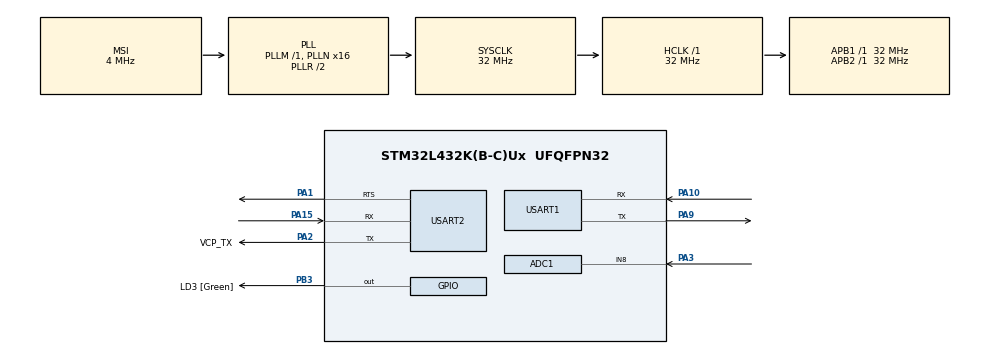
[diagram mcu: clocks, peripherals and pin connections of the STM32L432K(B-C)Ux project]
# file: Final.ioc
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ADC1.Channel-0\#ChannelRegularConversion=ADC_CHANNEL_8
ADC1.ContinuousConvMode=ENABLE
ADC1.NbrOfConversionFlag=1
ADC1.OffsetNumber-0\#ChannelRegularConversion=ADC_OFFSET_NONE
ADC1.Rank-0\#ChannelRegularConversion=1
ADC1.SamplingTime-0\#ChannelRegularConversion=ADC_SAMPLETIME_2CYCLES_5
ADC1.master=1
Mcu.Family=STM32L4
Mcu.Name=STM32L432K(B-C)Ux
Mcu.Package=UFQFPN32
NVIC.PriorityGroup=NVIC_PRIORITYGROUP_4
PA0.GPIO_Label=MCO [High speed clock in]
PA0.Mode=HSE-External-Clock-Source-for-LittleOrca
PA0.Signal=RCC_CK_IN
PA1.Mode=RTS_Only
PA1.Signal=USART2_RTS
PA10.Mode=Asynchronous
PA10.Signal=USART1_RX
PA13\ (JTMS-SWDIO).GPIO_Label=SWDIO
PA13\ (JTMS-SWDIO).Mode=Serial_Wire
PA13\ (JTMS-SWDIO).Signal=SYS_JTMS-SWDIO
PA14\ (JTCK-SWCLK).GPIO_Label=SWCLK
PA14\ (JTCK-SWCLK).Mode=Serial_Wire
PA14\ (JTCK-SWCLK).Signal=SYS_JTCK-SWCLK
PA15\ (JTDI).Mode=Asynchronous
PA15\ (JTDI).Signal=USART2_RX
PA2.GPIO_Label=VCP_TX
PA2.Mode=Asynchronous
PA2.Signal=USART2_TX
PA3.Signal=ADCx_IN8
PA9.Mode=Asynchronous
PA9.Signal=USART1_TX
PB3\ (JTDO-TRACESWO).GPIO_Label=LD3 [Green]
PB3\ (JTDO-TRACESWO).Signal=GPIO_Output
PC14-OSC32_IN\ (PC14).Mode=LSE-External-Oscillator
PC14-OSC32_IN\ (PC14).Signal=RCC_OSC32_IN
PC15-OSC32_OUT\ (PC15).Mode=LSE-External-Oscillator
PC15-OSC32_OUT\ (PC15).Signal=RCC_OSC32_OUT
ProjectManager.HeapSize=0x200
ProjectManager.StackSize=0x400
ProjectManager.TargetToolchain=TrueSTUDIO
RCC.AHBFreq_Value=32000000
RCC.APB1Freq_Value=32000000
RCC.APB1TimFreq_Value=32000000
RCC.APB2Freq_Value=32000000
RCC.APB2TimFreq_Value=32000000
RCC.CortexFreq_Value=32000000
RCC.HCLKFreq_Value=32000000
RCC.HSE_VALUE=8000000
RCC.HSI16_VALUE=16000000
RCC.HSI48_VALUE=48000000
RCC.HSI_VALUE=16000000
RCC.MSI_VALUE=4000000
RCC.PLLMUL=RCC_PLLMUL_4
RCC.PLLN=16
RCC.SYSCLKFreq_VALUE=32000000
RCC.SYSCLKSource=RCC_SYSCLKSOURCE_PLLCLK
RCC.VCOOutputFreq_Value=64000000
SH.ADCx_IN8.0=ADC1_IN8,IN8-Single-Ended
USART1.VirtualMode-Asynchronous=VM_ASYNC
USART2.VirtualMode-Asynchronous=VM_ASYNC
board=NUCLEO-L432KC

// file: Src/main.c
/* USER CODE BEGIN Header */
/**
 ******************************************************************************
 * @file           : main.c
 * @brief          : Main program body
 ******************************************************************************
 ** This notice applies to any and all portions of this file
 * that are not between comment pairs USER CODE BEGIN and
 * USER CODE END. Other portions of this file, whether
 * inserted by the user or by software development tools
 * are owned by their respective copyright owners.
 *
 * COPYRIGHT(c) 2019 STMicroelectronics
 *
 * Redistribution and use in source and binary forms, with or without modification,
 * are permitted provided that the following conditions are met:
 *   1. Redistributions of source code must retain the above copyright notice,
 *      this list of conditions and the following disclaimer.
 *   2. Redistributions in binary form must reproduce the above copyright notice,
 *      this list of conditions and the following disclaimer in the documentation
 *      and/or other materials provided with the distribution.
 *   3. Neither the name of STMicroelectronics nor the names of its contributors
 *      may be used to endorse or promote products derived from this software
 *      without specific prior written permission.
 *
 * THIS SOFTWARE IS PROVIDED BY THE COPYRIGHT HOLDERS AND CONTRIBUTORS "AS IS"
 * AND ANY EXPRESS OR IMPLIED WARRANTIES, INCLUDING, BUT NOT LIMITED TO, THE
 * IMPLIED WARRANTIES OF MERCHANTABILITY AND FITNESS FOR A PARTICULAR PURPOSE ARE
 * DISCLAIMED. IN NO EVENT SHALL THE COPYRIGHT HOLDER OR CONTRIBUTORS BE LIABLE
 * FOR ANY DIRECT, INDIRECT, INCIDENTAL, SPECIAL, EXEMPLARY, OR CONSEQUENTIAL
 * DAMAGES (INCLUDING, BUT NOT LIMITED TO, PROCUREMENT OF SUBSTITUTE GOODS OR
 * SERVICES; LOSS OF USE, DATA, OR PROFITS; OR BUSINESS INTERRUPTION) HOWEVER
 * CAUSED AND ON ANY THEORY OF LIABILITY, WHETHER IN CONTRACT, STRICT LIABILITY,
 * OR TORT (INCLUDING NEGLIGENCE OR OTHERWISE) ARISING IN ANY WAY OUT OF THE USE
 * OF THIS SOFTWARE, EVEN IF ADVISED OF THE POSSIBILITY OF SUCH DAMAGE.
 *
 ******************************************************************************
 */
/* USER CODE END Header */

#include "main.h"
#include "stm32l4xx_hal.h"
#include "math.h"
#define ADC_READING      4096
#define REF_VOLTAGE      3.3
#define REF_RESISTANCE   1650
#define LUX_SCALAR       12518931
#define LUX_CALC         -1.405

unsigned char start_delimeter = 0x7E;
unsigned char length_MSB = 0x00;
unsigned char length_LSB = 0x0C;
unsigned char frame_type = 0x01;		//Transmit Request Frame, API identifier
unsigned char frame_id = 0x01;//Identifies data frame to enable respond frame, API Frame ID
unsigned char option = 0x00;
unsigned char destination_add_MSB = 0xAB;
unsigned char destination_add_LSB = 0x01;

ADC_HandleTypeDef hadc1;

UART_HandleTypeDef huart1;
UART_HandleTypeDef huart2;

void SystemClock_Config(void);
static void MX_GPIO_Init(void);
static void MX_ADC1_Init(void);
static void MX_USART1_UART_Init(void);
static void MX_USART2_UART_Init(void);
void HAL_ADC_ConvCpltCallback(ADC_HandleTypeDef* hadc);
int get_adc_value(void);
void send_to_pc(int adc_value);
void adc_channel(int channel);
int get_sorted_value();
int calculate_lux(int adc_value);

volatile uint16_t adc_value = 0;
int lux;

void send_to_xbee(char dataHexa[8]) {
	int sum2 = 0x00;
	int sum1 = frame_type + frame_id + destination_add_MSB + destination_add_LSB
			+ option;
	for (int i = 0; i < strlen(dataHexa); i++) {
		sum2 += dataHexa[i];
	}
	int sum = 0;
	sum = sum1 + sum2;
	unsigned char two_last_digit = sum & 0xFF;
	unsigned char checksum = 255 - two_last_digit;
	unsigned char message[16] = { start_delimeter, length_MSB, length_LSB,
			frame_type, frame_id, destination_add_MSB, destination_add_LSB,
			option, 0, 0, 0, 0, 0, 0, 0, checksum };
	for (int i = 0; i < 7; i++) {
		message[8 + i] = dataHexa[i];
	}
	HAL_UART_Transmit(&huart1, message, 16, 100);
	HAL_UART_Transmit(&huart2, message, 16, 100);
}

int main(void) {

	/* MCU Configuration--------------------------------------------------------*/

	/* Reset of all peripherals, Initializes the Flash interface and the Systick. */
	HAL_Init();

	/* Configure the system clock */
	SystemClock_Config();

	/* Initialize all configured peripherals */
	MX_GPIO_Init();
	MX_ADC1_Init();
	MX_USART1_UART_Init();
	MX_USART2_UART_Init();
//HAL_ADC_Start_IT(&hadc1);
//HAL_ADC_ConvCpltCallback(&hadc1);
	/* Infinite loop */
	/* USER CODE BEGIN WHILE */
	while (1) {

		char msg1[8]="";
		adc_channel(8);
		adc_value = get_sorted_value();
		lux = adc_value;
		 //lux=adc_value/100;
		//send_to_pc(lux);
		/* USER CODE BEGIN 3 */
		sprintf(msg1, "%d", lux);
		send_to_xbee(msg1);
		HAL_Delay(3000);
	}
	/* USER CODE END 3 */
}

int calculate_lux(int adc_value) {
	int vol1, ldr_vol, lux, ldr_resistor;
	vol1 = adc_value / ADC_READING * REF_VOLTAGE;
	ldr_vol = REF_VOLTAGE - vol1;
	ldr_resistor = ldr_vol / vol1 * REF_RESISTANCE;
	lux = LUX_SCALAR * pow(ldr_resistor, LUX_CALC);
	return lux;
}
int get_sorted_value() {
	int raw_value[5] = { 0 };
	int i = 0;
	int k = 0;
	int apu = 0;

	for (k = 0; k < 4; k++) {
		raw_value[k] = get_adc_value();
		HAL_Delay(100);
	}

	for (k = 0; k < 4; k++) {
		for (i = 0; i < 4; i++) {
			if (raw_value[i] > raw_value[i + 1]) {
				apu = raw_value[i];
				raw_value[i] = raw_value[i + 1];
				raw_value[i + 1] = apu;
			} else {

			}
		}
	}
	return raw_value[2];
}
void HAL_ADC_ConvCpltCallback(ADC_HandleTypeDef* hadc) {
	if (hadc->Instance == hadc1.Instance) {
		adc_value = HAL_ADC_GetValue(hadc);
	}
}

void send_to_pc(int lux) {
	char msg6[] = { "Lux: " };
	HAL_UART_Transmit(&huart2, (uint8_t*) msg6, 5, 10);
	char msg1[1] = { 0 };
	sprintf(msg1, "%d", lux);
	HAL_UART_Transmit(&huart2, (uint8_t*) msg1, 4, 10);
}
int get_adc_value(void) {
	HAL_ADC_Start(&hadc1);
	HAL_ADC_PollForConversion(&hadc1, 10000);
	adc_value = HAL_ADC_GetValue(&hadc1);
	HAL_ADC_Stop(&hadc1);
	return adc_value;
}

void adc_channel(int channel) {
	ADC_ChannelConfTypeDef sConfig;
	sConfig.Channel = ADC_CHANNEL_8;
	sConfig.Rank = ADC_REGULAR_RANK_1;
	sConfig.SamplingTime = ADC_SAMPLETIME_2CYCLES_5;
	sConfig.SingleDiff = ADC_SINGLE_ENDED;
	sConfig.OffsetNumber = ADC_OFFSET_NONE;
	sConfig.Offset = 0;
	HAL_ADC_ConfigChannel(&hadc1, &sConfig);

}
void SystemClock_Config(void) {
	RCC_OscInitTypeDef RCC_OscInitStruct = { 0 };
	RCC_ClkInitTypeDef RCC_ClkInitStruct = { 0 };
	RCC_PeriphCLKInitTypeDef PeriphClkInit = { 0 };

	/**Configure LSE Drive Capability
	 */
	HAL_PWR_EnableBkUpAccess();
	__HAL_RCC_LSEDRIVE_CONFIG(RCC_LSEDRIVE_LOW);
	/**Initializes the CPU, AHB and APB busses clocks
	 */
	RCC_OscInitStruct.OscillatorType = RCC_OSCILLATORTYPE_LSE
			| RCC_OSCILLATORTYPE_MSI;
	RCC_OscInitStruct.LSEState = RCC_LSE_ON;
	RCC_OscInitStruct.MSIState = RCC_MSI_ON;
	RCC_OscInitStruct.MSICalibrationValue = 0;
	RCC_OscInitStruct.MSIClockRange = RCC_MSIRANGE_6;
	RCC_OscInitStruct.PLL.PLLState = RCC_PLL_ON;
	RCC_OscInitStruct.PLL.PLLSource = RCC_PLLSOURCE_MSI;
	RCC_OscInitStruct.PLL.PLLM = 1;
	RCC_OscInitStruct.PLL.PLLN = 16;
	RCC_OscInitStruct.PLL.PLLP = RCC_PLLP_DIV7;
	RCC_OscInitStruct.PLL.PLLQ = RCC_PLLQ_DIV2;
	RCC_OscInitStruct.PLL.PLLR = RCC_PLLR_DIV2;
	if (HAL_RCC_OscConfig(&RCC_OscInitStruct) != HAL_OK) {
		Error_Handler();
	}
	/**Initializes the CPU, AHB and APB busses clocks
	 */
	RCC_ClkInitStruct.ClockType = RCC_CLOCKTYPE_HCLK | RCC_CLOCKTYPE_SYSCLK
			| RCC_CLOCKTYPE_PCLK1 | RCC_CLOCKTYPE_PCLK2;
	RCC_ClkInitStruct.SYSCLKSource = RCC_SYSCLKSOURCE_PLLCLK;
	RCC_ClkInitStruct.AHBCLKDivider = RCC_SYSCLK_DIV1;
	RCC_ClkInitStruct.APB1CLKDivider = RCC_HCLK_DIV1;
	RCC_ClkInitStruct.APB2CLKDivider = RCC_HCLK_DIV1;

	if (HAL_RCC_ClockConfig(&RCC_ClkInitStruct, FLASH_LATENCY_1) != HAL_OK) {
		Error_Handler();
	}
	PeriphClkInit.PeriphClockSelection = RCC_PERIPHCLK_USART1
			| RCC_PERIPHCLK_USART2 | RCC_PERIPHCLK_ADC;
	PeriphClkInit.Usart1ClockSelection = RCC_USART1CLKSOURCE_PCLK2;
	PeriphClkInit.Usart2ClockSelection = RCC_USART2CLKSOURCE_PCLK1;
	PeriphClkInit.AdcClockSelection = RCC_ADCCLKSOURCE_PLLSAI1;
	PeriphClkInit.PLLSAI1.PLLSAI1Source = RCC_PLLSOURCE_MSI;
	PeriphClkInit.PLLSAI1.PLLSAI1M = 1;
	PeriphClkInit.PLLSAI1.PLLSAI1N = 16;
	PeriphClkInit.PLLSAI1.PLLSAI1P = RCC_PLLP_DIV7;
	PeriphClkInit.PLLSAI1.PLLSAI1Q = RCC_PLLQ_DIV2;
	PeriphClkInit.PLLSAI1.PLLSAI1R = RCC_PLLR_DIV2;
	PeriphClkInit.PLLSAI1.PLLSAI1ClockOut = RCC_PLLSAI1_ADC1CLK;
	if (HAL_RCCEx_PeriphCLKConfig(&PeriphClkInit) != HAL_OK) {
		Error_Handler();
	}
	/**Configure the main internal regulator output voltage
	 */
	if (HAL_PWREx_ControlVoltageScaling(PWR_REGULATOR_VOLTAGE_SCALE1)
			!= HAL_OK) {
		Error_Handler();
	}
	/**Enable MSI Auto calibration
	 */
	HAL_RCCEx_EnableMSIPLLMode();
}

static void MX_ADC1_Init(void) {

	ADC_ChannelConfTypeDef sConfig = { 0 };

	/**Common config
	 */
	hadc1.Instance = ADC1;
	hadc1.Init.ClockPrescaler = ADC_CLOCK_ASYNC_DIV2;
	hadc1.Init.Resolution = ADC_RESOLUTION_12B;
	hadc1.Init.DataAlign = ADC_DATAALIGN_RIGHT;
	hadc1.Init.ScanConvMode = ADC_SCAN_DISABLE;
	hadc1.Init.EOCSelection = ADC_EOC_SINGLE_CONV;
	hadc1.Init.LowPowerAutoWait = DISABLE;
	hadc1.Init.ContinuousConvMode = ENABLE;
	hadc1.Init.NbrOfConversion = 1;
	hadc1.Init.DiscontinuousConvMode = DISABLE;
	hadc1.Init.ExternalTrigConv = ADC_SOFTWARE_START;
	hadc1.Init.ExternalTrigConvEdge = ADC_EXTERNALTRIGCONVEDGE_NONE;
	hadc1.Init.DMAContinuousRequests = DISABLE;
	hadc1.Init.Overrun = ADC_OVR_DATA_PRESERVED;
	hadc1.Init.OversamplingMode = DISABLE;
	if (HAL_ADC_Init(&hadc1) != HAL_OK) {
		Error_Handler();
	}
	/**Configure Regular Channel
	 */
	sConfig.Channel = ADC_CHANNEL_8;
	sConfig.Rank = ADC_REGULAR_RANK_1;
	sConfig.SamplingTime = ADC_SAMPLETIME_2CYCLES_5;
	sConfig.SingleDiff = ADC_SINGLE_ENDED;
	sConfig.OffsetNumber = ADC_OFFSET_NONE;
	sConfig.Offset = 0;
	if (HAL_ADC_ConfigChannel(&hadc1, &sConfig) != HAL_OK) {
		Error_Handler();
	}

}

static void MX_USART1_UART_Init(void) {

	huart1.Instance = USART1;
	huart1.Init.BaudRate = 115200;
	huart1.Init.WordLength = UART_WORDLENGTH_8B;
	huart1.Init.StopBits = UART_STOPBITS_1;
	huart1.Init.Parity = UART_PARITY_NONE;
	huart1.Init.Mode = UART_MODE_TX_RX;
	huart1.Init.HwFlowCtl = UART_HWCONTROL_NONE;
	huart1.Init.OverSampling = UART_OVERSAMPLING_16;
	huart1.Init.OneBitSampling = UART_ONE_BIT_SAMPLE_DISABLE;
	huart1.AdvancedInit.AdvFeatureInit = UART_ADVFEATURE_NO_INIT;
	if (HAL_UART_Init(&huart1) != HAL_OK) {
		Error_Handler();
	}

}

static void MX_USART2_UART_Init(void) {

	huart2.Instance = USART2;
	huart2.Init.BaudRate = 115200;
	huart2.Init.WordLength = UART_WORDLENGTH_8B;
	huart2.Init.StopBits = UART_STOPBITS_1;
	huart2.Init.Parity = UART_PARITY_NONE;
	huart2.Init.Mode = UART_MODE_TX_RX;
	huart2.Init.HwFlowCtl = UART_HWCONTROL_RTS;
	huart2.Init.OverSampling = UART_OVERSAMPLING_16;
	huart2.Init.OneBitSampling = UART_ONE_BIT_SAMPLE_DISABLE;
	huart2.AdvancedInit.AdvFeatureInit = UART_ADVFEATURE_NO_INIT;
	if (HAL_UART_Init(&huart2) != HAL_OK) {
		Error_Handler();
	}

}

static void MX_GPIO_Init(void) {
	GPIO_InitTypeDef GPIO_InitStruct = { 0 };

	/* GPIO Ports Clock Enable */
	__HAL_RCC_GPIOC_CLK_ENABLE()
	;
	__HAL_RCC_GPIOA_CLK_ENABLE()
	;
	__HAL_RCC_GPIOB_CLK_ENABLE()
	;

	/*Configure GPIO pin Output Level */
	HAL_GPIO_WritePin(LD3_GPIO_Port, LD3_Pin, GPIO_PIN_RESET);

	/*Configure GPIO pin : LD3_Pin */
	GPIO_InitStruct.Pin = LD3_Pin;
	GPIO_InitStruct.Mode = GPIO_MODE_OUTPUT_PP;
	GPIO_InitStruct.Pull = GPIO_NOPULL;
	GPIO_InitStruct.Speed = GPIO_SPEED_FREQ_LOW;
	HAL_GPIO_Init(LD3_GPIO_Port, &GPIO_InitStruct);

}

void Error_Handler(void) {
}

/************************ (C) COPYRIGHT STMicroelectronics *****END OF FILE****/
